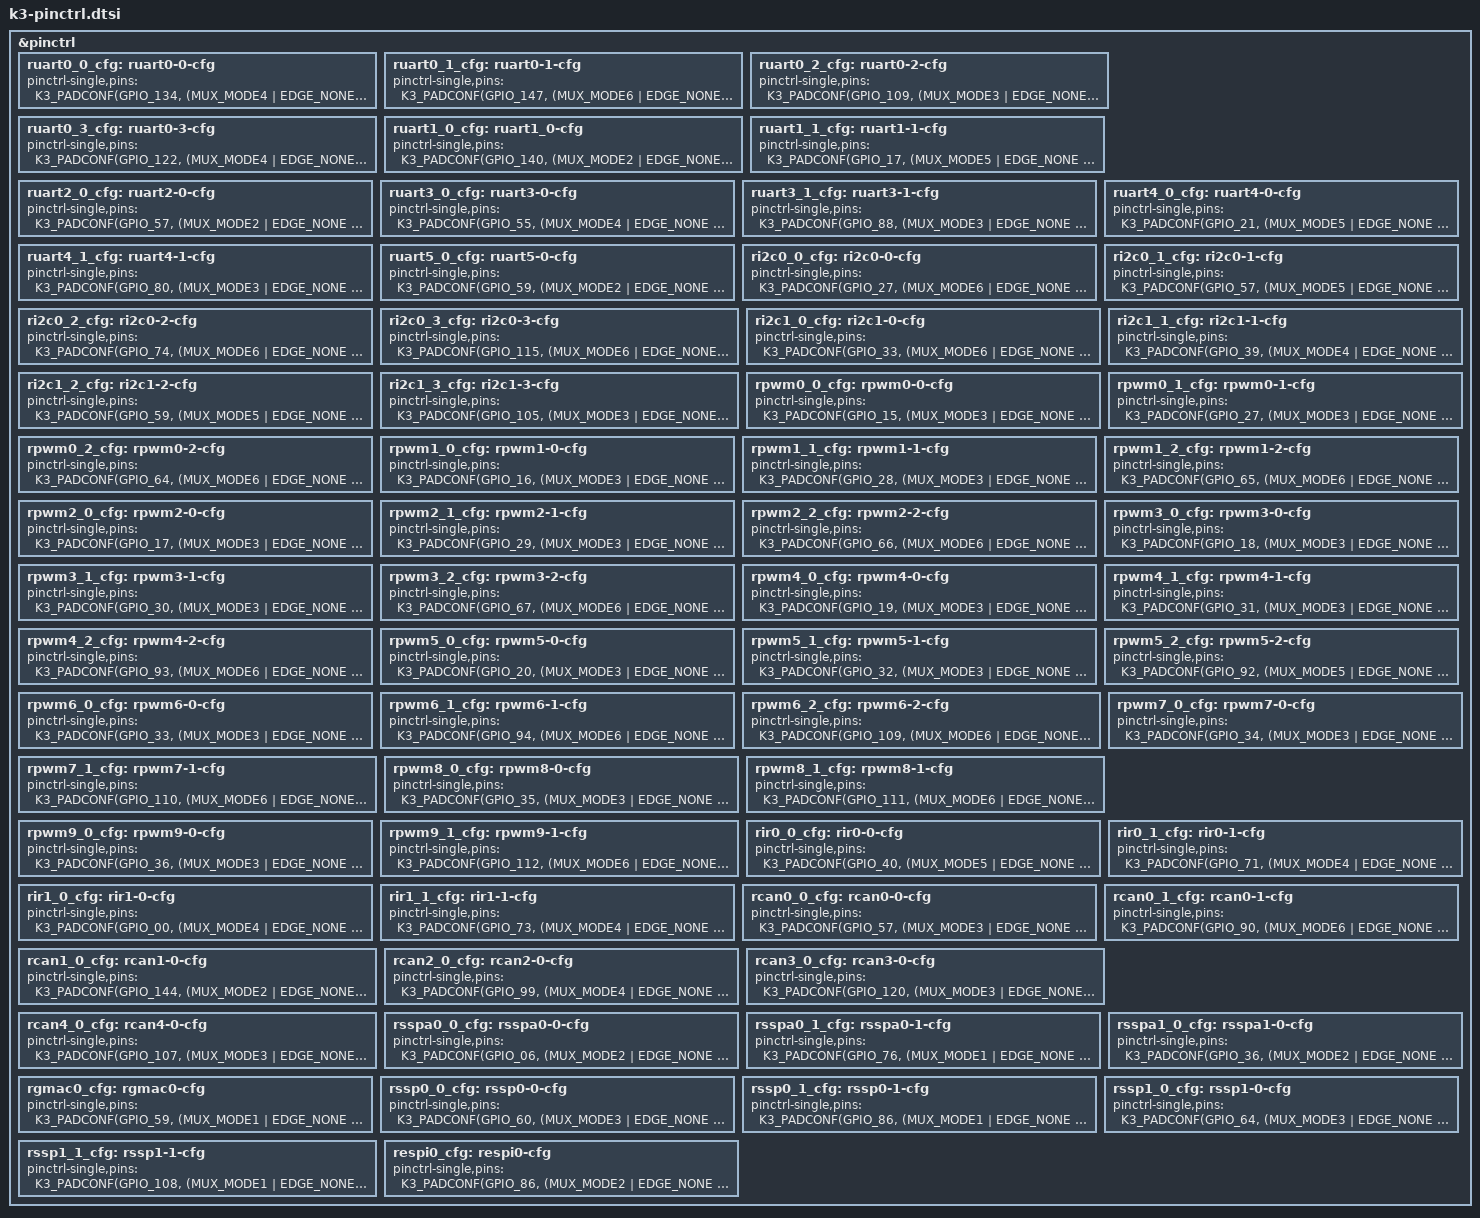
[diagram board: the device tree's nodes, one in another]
#include "k3-pinctrl.h"

&pinctrl {
  ruart0_0_cfg: ruart0-0-cfg {
      pinctrl-single,pins = <
          K3_PADCONF(GPIO_134, (MUX_MODE4 | EDGE_NONE | PULL_UP | PAD_DS8))     /* r_uart0_tx */
          K3_PADCONF(GPIO_135, (MUX_MODE4 | EDGE_NONE | PULL_UP | PAD_DS8))     /* r_uart0_rx */
      >;
  };

  ruart0_1_cfg: ruart0-1-cfg {
      pinctrl-single,pins = <
          K3_PADCONF(GPIO_147, (MUX_MODE6 | EDGE_NONE | PULL_UP | PAD_DS8))     /* r_uart0_tx */
          K3_PADCONF(GPIO_148, (MUX_MODE6 | EDGE_NONE | PULL_UP | PAD_DS8))     /* r_uart0_rx */
      >;
  };

  ruart0_2_cfg: ruart0-2-cfg {
      pinctrl-single,pins = <
          K3_PADCONF(GPIO_109, (MUX_MODE3 | EDGE_NONE | PULL_UP | PAD_DS8))     /* r_uart0_tx */
          K3_PADCONF(GPIO_110, (MUX_MODE3 | EDGE_NONE | PULL_UP | PAD_DS8))     /* r_uart0_rx */
      >;
  };

  ruart0_3_cfg: ruart0-3-cfg {
      pinctrl-single,pins = <
          K3_PADCONF(GPIO_122, (MUX_MODE4 | EDGE_NONE | PULL_UP | PAD_DS8))     /* r_uart0_tx */
          K3_PADCONF(GPIO_123, (MUX_MODE4 | EDGE_NONE | PULL_UP | PAD_DS8))     /* r_uart0_rx */
      >;
  };
  ruart1_0_cfg: ruart1_0-cfg {
      pinctrl-single,pins = <
          K3_PADCONF(GPIO_140, (MUX_MODE2 | EDGE_NONE | PULL_UP | PAD_DS8))    /* ruart1 rts */
          K3_PADCONF(GPIO_141, (MUX_MODE2 | EDGE_NONE | PULL_UP | PAD_DS8))    /* ruart1 cts */
          K3_PADCONF(GPIO_142, (MUX_MODE2 | EDGE_NONE | PULL_UP | PAD_DS8))    /* ruart1 rx */
          K3_PADCONF(GPIO_143, (MUX_MODE2 | EDGE_NONE | PULL_UP | PAD_DS8))    /* ruart1 tx */
      >;
  };

  ruart1_1_cfg: ruart1-1-cfg {
      pinctrl-single,pins = <
          K3_PADCONF(GPIO_17, (MUX_MODE5 | EDGE_NONE | PULL_UP | PAD_DS8))     /* ruart1 tx */
          K3_PADCONF(GPIO_18, (MUX_MODE5 | EDGE_NONE | PULL_UP | PAD_DS8))     /* ruart1 rx */
          K3_PADCONF(GPIO_19, (MUX_MODE5 | EDGE_NONE | PULL_UP | PAD_DS8))     /* ruart1 cts */
          K3_PADCONF(GPIO_20, (MUX_MODE5 | EDGE_NONE | PULL_UP | PAD_DS8))     /* ruart1 rts */
      >;
  };

  ruart2_0_cfg: ruart2-0-cfg {
      pinctrl-single,pins = <
          K3_PADCONF(GPIO_57, (MUX_MODE2 | EDGE_NONE | PULL_UP | PAD_DS8))     /* ruart2 tx */
          K3_PADCONF(GPIO_58, (MUX_MODE2 | EDGE_NONE | PULL_UP | PAD_DS8))     /* ruart2 rx */
      >;
  };

  ruart3_0_cfg: ruart3-0-cfg {
      pinctrl-single,pins = <
          K3_PADCONF(GPIO_55, (MUX_MODE4 | EDGE_NONE | PULL_UP | PAD_DS8))     /* ruart3 rx */
          K3_PADCONF(GPIO_56, (MUX_MODE4 | EDGE_NONE | PULL_UP | PAD_DS8))     /* ruart3 tx */
      >;
  };

  ruart3_1_cfg: ruart3-1-cfg {
      pinctrl-single,pins = <
          K3_PADCONF(GPIO_88, (MUX_MODE3 | EDGE_NONE | PULL_UP | PAD_DS8))     /* ruart3 tx */
          K3_PADCONF(GPIO_89, (MUX_MODE3 | EDGE_NONE | PULL_UP | PAD_DS8))     /* ruart3 rx */
      >;
  };

  ruart4_0_cfg: ruart4-0-cfg {
      pinctrl-single,pins = <
          K3_PADCONF(GPIO_21, (MUX_MODE5 | EDGE_NONE | PULL_UP | PAD_DS8))     /* ruart4 tx */
          K3_PADCONF(GPIO_22, (MUX_MODE5 | EDGE_NONE | PULL_UP | PAD_DS8))     /* ruart4 rx */
      >;
  };

  ruart4_1_cfg: ruart4-1-cfg {
      pinctrl-single,pins = <
          K3_PADCONF(GPIO_80, (MUX_MODE3 | EDGE_NONE | PULL_UP | PAD_DS8))     /* ruart4 tx */
          K3_PADCONF(GPIO_81, (MUX_MODE3 | EDGE_NONE | PULL_UP | PAD_DS8))     /* ruart4 rx */
      >;
  };

  ruart5_0_cfg: ruart5-0-cfg {
      pinctrl-single,pins = <
          K3_PADCONF(GPIO_59, (MUX_MODE2 | EDGE_NONE | PULL_UP | PAD_DS8))     /* ruart5 rx */
          K3_PADCONF(GPIO_60, (MUX_MODE2 | EDGE_NONE | PULL_UP | PAD_DS8))     /* ruart5 tx */
      >;
  };

  ri2c0_0_cfg: ri2c0-0-cfg {
      pinctrl-single,pins = <
          K3_PADCONF(GPIO_27, (MUX_MODE6 | EDGE_NONE | PULL_UP | PAD_DS8))    /* ri2c0 scl */
          K3_PADCONF(GPIO_28, (MUX_MODE6 | EDGE_NONE | PULL_UP | PAD_DS8))    /* ri2c0 sda */
      >;
  };

  ri2c0_1_cfg: ri2c0-1-cfg {
      pinctrl-single,pins = <
          K3_PADCONF(GPIO_57, (MUX_MODE5 | EDGE_NONE | PULL_UP | PAD_DS8))    /* ri2c0 scl */
          K3_PADCONF(GPIO_58, (MUX_MODE5 | EDGE_NONE | PULL_UP | PAD_DS8))    /* ri2c0 sda */
      >;
  };

  ri2c0_2_cfg: ri2c0-2-cfg {
      pinctrl-single,pins = <
          K3_PADCONF(GPIO_74, (MUX_MODE6 | EDGE_NONE | PULL_UP | PAD_DS8))    /* ri2c0 scl */
          K3_PADCONF(GPIO_75, (MUX_MODE6 | EDGE_NONE | PULL_UP | PAD_DS8))    /* ri2c0 sda */
      >;
  };

  ri2c0_3_cfg: ri2c0-3-cfg {
      pinctrl-single,pins = <
          K3_PADCONF(GPIO_115, (MUX_MODE6 | EDGE_NONE | PULL_UP | PAD_DS8))   /* ri2c0 scl */
          K3_PADCONF(GPIO_116, (MUX_MODE6 | EDGE_NONE | PULL_UP | PAD_DS8))   /* ri2c0 sda */
      >;
  };

  ri2c1_0_cfg: ri2c1-0-cfg {
      pinctrl-single,pins = <
          K3_PADCONF(GPIO_33, (MUX_MODE6 | EDGE_NONE | PULL_UP | PAD_DS8))    /* ri2c1 scl */
          K3_PADCONF(GPIO_34, (MUX_MODE6 | EDGE_NONE | PULL_UP | PAD_DS8))    /* ri2c1 sda */
      >;
  };

  ri2c1_1_cfg: ri2c1-1-cfg {
      pinctrl-single,pins = <
          K3_PADCONF(GPIO_39, (MUX_MODE4 | EDGE_NONE | PULL_UP | PAD_DS8))    /* ri2c1 scl */
          K3_PADCONF(GPIO_40, (MUX_MODE4 | EDGE_NONE | PULL_UP | PAD_DS8))    /* ri2c1 sda */
      >;
  };

  ri2c1_2_cfg: ri2c1-2-cfg {
      pinctrl-single,pins = <
          K3_PADCONF(GPIO_59, (MUX_MODE5 | EDGE_NONE | PULL_UP | PAD_DS8))    /* ri2c1 scl */
          K3_PADCONF(GPIO_60, (MUX_MODE5 | EDGE_NONE | PULL_UP | PAD_DS8))    /* ri2c1 sda */
      >;
  };

  ri2c1_3_cfg: ri2c1-3-cfg {
      pinctrl-single,pins = <
          K3_PADCONF(GPIO_105, (MUX_MODE3 | EDGE_NONE | PULL_UP | PAD_DS8))   /* ri2c1 scl */
          K3_PADCONF(GPIO_106, (MUX_MODE3 | EDGE_NONE | PULL_UP | PAD_DS8))   /* ri2c1 sda */
      >;
  };

  rpwm0_0_cfg: rpwm0-0-cfg {
      pinctrl-single,pins = <
          K3_PADCONF(GPIO_15, (MUX_MODE3 | EDGE_NONE | PULL_UP | PAD_DS8))    /* rpwm0 */
      >;
  };

  rpwm0_1_cfg: rpwm0-1-cfg {
      pinctrl-single,pins = <
          K3_PADCONF(GPIO_27, (MUX_MODE3 | EDGE_NONE | PULL_UP | PAD_DS8))    /* rpwm0 */
      >;
  };

  rpwm0_2_cfg: rpwm0-2-cfg {
      pinctrl-single,pins = <
          K3_PADCONF(GPIO_64, (MUX_MODE6 | EDGE_NONE | PULL_UP | PAD_DS8))    /* rpwm0 */
      >;
  };

  rpwm1_0_cfg: rpwm1-0-cfg {
      pinctrl-single,pins = <
          K3_PADCONF(GPIO_16, (MUX_MODE3 | EDGE_NONE | PULL_UP | PAD_DS8))    /* rpwm1 */
      >;
  };

  rpwm1_1_cfg: rpwm1-1-cfg {
      pinctrl-single,pins = <
          K3_PADCONF(GPIO_28, (MUX_MODE3 | EDGE_NONE | PULL_UP | PAD_DS8))    /* rpwm1 */
      >;
  };

  rpwm1_2_cfg: rpwm1-2-cfg {
      pinctrl-single,pins = <
          K3_PADCONF(GPIO_65, (MUX_MODE6 | EDGE_NONE | PULL_UP | PAD_DS8))    /* rpwm1 */
      >;
  };

  rpwm2_0_cfg: rpwm2-0-cfg {
      pinctrl-single,pins = <
          K3_PADCONF(GPIO_17, (MUX_MODE3 | EDGE_NONE | PULL_UP | PAD_DS8))    /* rpwm2 */
      >;
  };

  rpwm2_1_cfg: rpwm2-1-cfg {
      pinctrl-single,pins = <
          K3_PADCONF(GPIO_29, (MUX_MODE3 | EDGE_NONE | PULL_UP | PAD_DS8))    /* rpwm2 */
      >;
  };

  rpwm2_2_cfg: rpwm2-2-cfg {
      pinctrl-single,pins = <
          K3_PADCONF(GPIO_66, (MUX_MODE6 | EDGE_NONE | PULL_UP | PAD_DS8))    /* rpwm2 */
      >;
  };

  rpwm3_0_cfg: rpwm3-0-cfg {
      pinctrl-single,pins = <
          K3_PADCONF(GPIO_18, (MUX_MODE3 | EDGE_NONE | PULL_UP | PAD_DS8))    /* rpwm3 */
      >;
  };

  rpwm3_1_cfg: rpwm3-1-cfg {
      pinctrl-single,pins = <
          K3_PADCONF(GPIO_30, (MUX_MODE3 | EDGE_NONE | PULL_UP | PAD_DS8))    /* rpwm3 */
      >;
  };

  rpwm3_2_cfg: rpwm3-2-cfg {
      pinctrl-single,pins = <
          K3_PADCONF(GPIO_67, (MUX_MODE6 | EDGE_NONE | PULL_UP | PAD_DS8))    /* rpwm3 */
      >;
  };

  rpwm4_0_cfg: rpwm4-0-cfg {
      pinctrl-single,pins = <
          K3_PADCONF(GPIO_19, (MUX_MODE3 | EDGE_NONE | PULL_UP | PAD_DS8))    /* rpwm4 */
      >;
  };

  rpwm4_1_cfg: rpwm4-1-cfg {
      pinctrl-single,pins = <
          K3_PADCONF(GPIO_31, (MUX_MODE3 | EDGE_NONE | PULL_UP | PAD_DS8))    /* rpwm4 */
      >;
  };

  rpwm4_2_cfg: rpwm4-2-cfg {
      pinctrl-single,pins = <
          K3_PADCONF(GPIO_93, (MUX_MODE6 | EDGE_NONE | PULL_UP | PAD_DS8))    /* rpwm4 */
      >;
  };

  rpwm5_0_cfg: rpwm5-0-cfg {
      pinctrl-single,pins = <
          K3_PADCONF(GPIO_20, (MUX_MODE3 | EDGE_NONE | PULL_UP | PAD_DS8))    /* rpwm5 */
      >;
  };

  rpwm5_1_cfg: rpwm5-1-cfg {
      pinctrl-single,pins = <
          K3_PADCONF(GPIO_32, (MUX_MODE3 | EDGE_NONE | PULL_UP | PAD_DS8))    /* rpwm5 */
      >;
  };

  rpwm5_2_cfg: rpwm5-2-cfg {
      pinctrl-single,pins = <
          K3_PADCONF(GPIO_92, (MUX_MODE5 | EDGE_NONE | PULL_UP | PAD_DS8))    /* rpwm5 */
      >;
  };

  rpwm6_0_cfg: rpwm6-0-cfg {
      pinctrl-single,pins = <
          K3_PADCONF(GPIO_33, (MUX_MODE3 | EDGE_NONE | PULL_UP | PAD_DS8))    /* rpwm6 */
      >;
  };

  rpwm6_1_cfg: rpwm6-1-cfg {
      pinctrl-single,pins = <
          K3_PADCONF(GPIO_94, (MUX_MODE6 | EDGE_NONE | PULL_UP | PAD_DS8))    /* rpwm6 */
      >;
  };

  rpwm6_2_cfg: rpwm6-2-cfg {
      pinctrl-single,pins = <
          K3_PADCONF(GPIO_109, (MUX_MODE6 | EDGE_NONE | PULL_UP | PAD_DS8))   /* rpwm6 */
      >;
  };

  rpwm7_0_cfg: rpwm7-0-cfg {
      pinctrl-single,pins = <
          K3_PADCONF(GPIO_34, (MUX_MODE3 | EDGE_NONE | PULL_UP | PAD_DS8))    /* rpwm7 */
      >;
  };

  rpwm7_1_cfg: rpwm7-1-cfg {
      pinctrl-single,pins = <
          K3_PADCONF(GPIO_110, (MUX_MODE6 | EDGE_NONE | PULL_UP | PAD_DS8))   /* rpwm7 */
      >;
  };

  rpwm8_0_cfg: rpwm8-0-cfg {
      pinctrl-single,pins = <
          K3_PADCONF(GPIO_35, (MUX_MODE3 | EDGE_NONE | PULL_UP | PAD_DS8))    /* rpwm8 */
      >;
  };

  rpwm8_1_cfg: rpwm8-1-cfg {
      pinctrl-single,pins = <
          K3_PADCONF(GPIO_111, (MUX_MODE6 | EDGE_NONE | PULL_UP | PAD_DS8))   /* rpwm8 */
      >;
  };

  rpwm9_0_cfg: rpwm9-0-cfg {
      pinctrl-single,pins = <
          K3_PADCONF(GPIO_36, (MUX_MODE3 | EDGE_NONE | PULL_UP | PAD_DS8))    /* rpwm9 */
      >;
  };

  rpwm9_1_cfg: rpwm9-1-cfg {
      pinctrl-single,pins = <
          K3_PADCONF(GPIO_112, (MUX_MODE6 | EDGE_NONE | PULL_UP | PAD_DS8))   /* rpwm9 */
      >;
  };

  rir0_0_cfg: rir0-0-cfg {
      pinctrl-single,pins = <
          K3_PADCONF(GPIO_40, (MUX_MODE5 | EDGE_NONE | PULL_UP | PAD_DS8))    /* rir0 rx */
      >;
  };

  rir0_1_cfg: rir0-1-cfg {
      pinctrl-single,pins = <
          K3_PADCONF(GPIO_71, (MUX_MODE4 | EDGE_NONE | PULL_UP | PAD_DS8))    /* rir0 rx */
      >;
  };

  rir1_0_cfg: rir1-0-cfg {
      pinctrl-single,pins = <
          K3_PADCONF(GPIO_00, (MUX_MODE4 | EDGE_NONE | PULL_UP | PAD_DS8))     /* rir1 rx */
      >;
  };

  rir1_1_cfg: rir1-1-cfg {
      pinctrl-single,pins = <
          K3_PADCONF(GPIO_73, (MUX_MODE4 | EDGE_NONE | PULL_UP | PAD_DS8))    /* rir1 rx */
      >;
  };

  rcan0_0_cfg: rcan0-0-cfg {
      pinctrl-single,pins = <
          K3_PADCONF(GPIO_57, (MUX_MODE3 | EDGE_NONE | PULL_UP | PAD_DS8))    /* rcan0 rx */
          K3_PADCONF(GPIO_58, (MUX_MODE3 | EDGE_NONE | PULL_UP | PAD_DS8))    /* rcan0 tx */
      >;
  };

  rcan0_1_cfg: rcan0-1-cfg {
      pinctrl-single,pins = <
          K3_PADCONF(GPIO_90, (MUX_MODE6 | EDGE_NONE | PULL_UP | PAD_DS8))    /* rcan0 rx */
          K3_PADCONF(GPIO_91, (MUX_MODE6 | EDGE_NONE | PULL_UP | PAD_DS8))    /* rcan0 tx */
      >;
  };

  rcan1_0_cfg: rcan1-0-cfg {
      pinctrl-single,pins = <
          K3_PADCONF(GPIO_144, (MUX_MODE2 | EDGE_NONE | PULL_UP | PAD_DS8))   /* rcan1 rx */
          K3_PADCONF(GPIO_146, (MUX_MODE2 | EDGE_NONE | PULL_UP | PAD_DS8))   /* rcan1 tx */
      >;
  };

  rcan2_0_cfg: rcan2-0-cfg {
      pinctrl-single,pins = <
          K3_PADCONF(GPIO_99, (MUX_MODE4 | EDGE_NONE | PULL_UP | PAD_DS8))    /* rcan2 tx */
          K3_PADCONF(GPIO_100, (MUX_MODE4 | EDGE_NONE | PULL_UP | PAD_DS8))   /* rcan2 rx */
      >;
  };

  rcan3_0_cfg: rcan3-0-cfg {
      pinctrl-single,pins = <
          K3_PADCONF(GPIO_120, (MUX_MODE3 | EDGE_NONE | PULL_UP | PAD_DS8))   /* rcan3 tx */
          K3_PADCONF(GPIO_121, (MUX_MODE3 | EDGE_NONE | PULL_UP | PAD_DS8))   /* rcan3 rx */
      >;
  };

  rcan4_0_cfg: rcan4-0-cfg {
      pinctrl-single,pins = <
          K3_PADCONF(GPIO_107, (MUX_MODE3 | EDGE_NONE | PULL_UP | PAD_DS8))   /* rcan4 tx */
          K3_PADCONF(GPIO_108, (MUX_MODE3 | EDGE_NONE | PULL_UP | PAD_DS8))   /* rcan4 rx */
      >;
  };

  rsspa0_0_cfg: rsspa0-0-cfg {
      pinctrl-single,pins = <
          K3_PADCONF(GPIO_06,  (MUX_MODE2 | EDGE_NONE | PULL_UP | PAD_DS8))    /* rsspa0 clk */
          K3_PADCONF(GPIO_07,  (MUX_MODE2 | EDGE_NONE | PULL_UP | PAD_DS8))    /* rsspa0 frm */
          K3_PADCONF(GPIO_08,  (MUX_MODE2 | EDGE_NONE | PULL_UP | PAD_DS8))    /* rsspa0 tx */
          K3_PADCONF(GPIO_09,  (MUX_MODE2 | EDGE_NONE | PULL_UP | PAD_DS8))    /* rsspa0 rx */
          K3_PADCONF(GPIO_10, (MUX_MODE2 | EDGE_NONE | PULL_UP | PAD_DS8))    /* rsspa0 sysclk */
      >;
  };

  rsspa0_1_cfg: rsspa0-1-cfg {
      pinctrl-single,pins = <
          K3_PADCONF(GPIO_76, (MUX_MODE1 | EDGE_NONE | PULL_UP | PAD_DS8))    /* rsspa0 clk */
          K3_PADCONF(GPIO_77, (MUX_MODE1 | EDGE_NONE | PULL_UP | PAD_DS8))    /* rsspa0 frm */
          K3_PADCONF(GPIO_78, (MUX_MODE1 | EDGE_NONE | PULL_UP | PAD_DS8))    /* rsspa0 tx */
          K3_PADCONF(GPIO_79, (MUX_MODE1 | EDGE_NONE | PULL_UP | PAD_DS8))    /* rsspa0 rx */
          K3_PADCONF(GPIO_80, (MUX_MODE1 | EDGE_NONE | PULL_UP | PAD_DS8))    /* rsspa0 sysclk */
      >;
  };

  rsspa1_0_cfg: rsspa1-0-cfg {
      pinctrl-single,pins = <
          K3_PADCONF(GPIO_36, (MUX_MODE2 | EDGE_NONE | PULL_UP | PAD_DS8))    /* rsspa1 clk */
          K3_PADCONF(GPIO_37, (MUX_MODE2 | EDGE_NONE | PULL_UP | PAD_DS8))    /* rsspa1 frm */
          K3_PADCONF(GPIO_38, (MUX_MODE2 | EDGE_NONE | PULL_UP | PAD_DS8))    /* rsspa1 tx */
          K3_PADCONF(GPIO_39, (MUX_MODE2 | EDGE_NONE | PULL_UP | PAD_DS8))    /* rsspa1 rx */
          K3_PADCONF(GPIO_40, (MUX_MODE2 | EDGE_NONE | PULL_UP | PAD_DS8))    /* rsspa1 sysclk */
      >;
  };

  rgmac0_cfg: rgmac0-cfg {
      pinctrl-single,pins = <
          K3_PADCONF(GPIO_59, (MUX_MODE1 | EDGE_NONE | PULL_DIS | PAD_DS8))    /* rgmac0 rxdv */
          K3_PADCONF(GPIO_60, (MUX_MODE1 | EDGE_NONE | PULL_DIS | PAD_DS8))    /* rgmac0 rx d0 */
          K3_PADCONF(GPIO_61, (MUX_MODE1 | EDGE_NONE | PULL_DIS | PAD_DS8))    /* rgmac0 rx d1 */
          K3_PADCONF(GPIO_62, (MUX_MODE1 | EDGE_NONE | PULL_DIS | PAD_DS8))    /* rgmac0 rx clk */
          K3_PADCONF(GPIO_63, (MUX_MODE1 | EDGE_NONE | PULL_DIS | PAD_DS8))    /* rgmac0 rx d2 */
          K3_PADCONF(GPIO_64, (MUX_MODE1 | EDGE_NONE | PULL_DIS | PAD_DS8))    /* rgmac0 rx d3 */
          K3_PADCONF(GPIO_65, (MUX_MODE1 | EDGE_NONE | PULL_DIS | PAD_DS8))    /* rgmac0 tx d0 */
          K3_PADCONF(GPIO_66, (MUX_MODE1 | EDGE_NONE | PULL_DIS | PAD_DS8))    /* rgmac0 tx d1 */
          K3_PADCONF(GPIO_67, (MUX_MODE1 | EDGE_NONE | PULL_DIS | PAD_DS8))    /* rgmac0 tx clk */
          K3_PADCONF(GPIO_68, (MUX_MODE1 | EDGE_NONE | PULL_DIS | PAD_DS8))    /* rgmac0 tx d2 */
          K3_PADCONF(GPIO_69, (MUX_MODE1 | EDGE_NONE | PULL_DIS | PAD_DS8))    /* rgmac0 tx d3 */
          K3_PADCONF(GPIO_70, (MUX_MODE1 | EDGE_NONE | PULL_DIS | PAD_DS8))    /* rgmac0 tx en */
          K3_PADCONF(GPIO_71, (MUX_MODE1 | EDGE_NONE | PULL_DIS | PAD_DS8))    /* rgmac0 mdc */
          K3_PADCONF(GPIO_72, (MUX_MODE1 | EDGE_NONE | PULL_DIS | PAD_DS8))    /* rgmac0 mdio */
          K3_PADCONF(GPIO_73, (MUX_MODE1 | EDGE_NONE | PULL_DIS | PAD_DS8))    /* rgmac0 int */
          K3_PADCONF(GPIO_74, (MUX_MODE1 | EDGE_NONE | PULL_DIS | PAD_DS8))    /* rgmac0 clk ref */
      >;
  };

  rssp0_0_cfg: rssp0-0-cfg {
      pinctrl-single,pins = <
          K3_PADCONF(GPIO_60, (MUX_MODE3 | EDGE_NONE | PULL_DIS | PAD_DS8))   /* rssp0 tx */
          K3_PADCONF(GPIO_61, (MUX_MODE3 | EDGE_NONE | PULL_DIS | PAD_DS8))   /* rssp0 rx */
          K3_PADCONF(GPIO_62, (MUX_MODE3 | EDGE_NONE | PULL_DIS | PAD_DS8))   /* rssp0 clk */
          K3_PADCONF(GPIO_63, (MUX_MODE3 | EDGE_NONE | PULL_UP      | PAD_DS8))   /* rssp0 frm */
      >;
  };

  rssp0_1_cfg: rssp0-1-cfg {
      pinctrl-single,pins = <
          K3_PADCONF(GPIO_86, (MUX_MODE1 | EDGE_NONE | PULL_DIS | PAD_DS8))   /* rssp0 tx */
          K3_PADCONF(GPIO_87, (MUX_MODE1 | EDGE_NONE | PULL_DIS | PAD_DS8))   /* rssp0 rx */
          K3_PADCONF(GPIO_88, (MUX_MODE1 | EDGE_NONE | PULL_DIS | PAD_DS8))   /* rssp0 clk */
          K3_PADCONF(GPIO_89, (MUX_MODE1 | EDGE_NONE | PULL_UP      | PAD_DS8))   /* rssp0 frm */
      >;
  };

  rssp1_0_cfg: rssp1-0-cfg {
      pinctrl-single,pins = <
          K3_PADCONF(GPIO_64, (MUX_MODE3 | EDGE_NONE | PULL_DIS | PAD_DS8))   /* rssp1 tx */
          K3_PADCONF(GPIO_65, (MUX_MODE3 | EDGE_NONE | PULL_DIS | PAD_DS8))   /* rssp1 rx */
          K3_PADCONF(GPIO_66, (MUX_MODE3 | EDGE_NONE | PULL_DIS | PAD_DS8))   /* rssp1 clk */
          K3_PADCONF(GPIO_67, (MUX_MODE3 | EDGE_NONE | PULL_UP      | PAD_DS8))   /* rssp1 frm */
      >;
  };

  rssp1_1_cfg: rssp1-1-cfg {
      pinctrl-single,pins = <
          K3_PADCONF(GPIO_108, (MUX_MODE1 | EDGE_NONE | PULL_DIS | PAD_DS8))  /* rssp1 tx */
          K3_PADCONF(GPIO_109, (MUX_MODE1 | EDGE_NONE | PULL_DIS | PAD_DS8))  /* rssp1 rx */
          K3_PADCONF(GPIO_116, (MUX_MODE1 | EDGE_NONE | PULL_DIS | PAD_DS8))  /* rssp1 clk */
          K3_PADCONF(GPIO_117, (MUX_MODE1 | EDGE_NONE | PULL_UP      | PAD_DS8))  /* rssp1 frm */
      >;
  };

  respi0_cfg: respi0-cfg {
      pinctrl-single,pins = <
          K3_PADCONF(GPIO_86, (MUX_MODE2 | EDGE_NONE | PULL_UP   | PAD_DS8))   /* respi0 d0 */
          K3_PADCONF(GPIO_87, (MUX_MODE2 | EDGE_NONE | PULL_UP   | PAD_DS8))   /* respi0 d1 */
          K3_PADCONF(GPIO_88, (MUX_MODE2 | EDGE_NONE | PULL_UP   | PAD_DS8))   /* respi0 d2 */
          K3_PADCONF(GPIO_89, (MUX_MODE2 | EDGE_NONE | PULL_UP   | PAD_DS8))   /* respi0 d3 */
          K3_PADCONF(GPIO_90, (MUX_MODE2 | EDGE_NONE | PULL_UP   | PAD_DS8))   /* respi0 cs */
          K3_PADCONF(GPIO_92, (MUX_MODE2 | EDGE_NONE | PULL_UP   | PAD_DS8))   /* respi0 reset */
          K3_PADCONF(GPIO_93, (MUX_MODE2 | EDGE_NONE | PULL_UP   | PAD_DS8))   /* respi0 alert */
          K3_PADCONF(GPIO_91, (MUX_MODE2 | EDGE_NONE | PULL_DOWN | PAD_DS8))   /* respi0 clk */
      >;
  };
};

